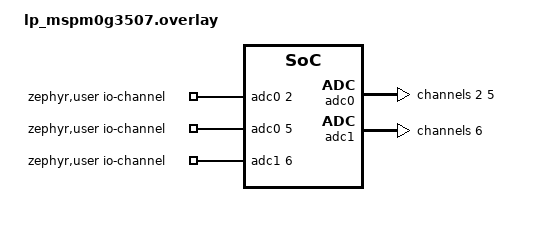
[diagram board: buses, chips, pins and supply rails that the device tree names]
/*
 * SPDX-License-Identifier: Apache-2.0
 */

/ {
	zephyr,user {
		/* adjust channel number according to pinmux in lp_mspm0g3507.dts */
		io-channels = <&adc0 2 &adc0 5 &adc1 6>;	/* I.e. A0.2 = PA25 */
	};
};

&adc0 {
	status = "okay";

	#address-cells = <1>;
	#size-cells = <0>;

	channel@2 {
		reg = <2>;
		zephyr,gain = "ADC_GAIN_1";
		zephyr,reference = "ADC_REF_INTERNAL";
		zephyr,acquisition-time = <ADC_ACQ_TIME(ADC_ACQ_TIME_TICKS, 500)>;
		zephyr,resolution = <12>;
	};

	channel@5 {
		reg = <5>;
		zephyr,gain = "ADC_GAIN_1";
		zephyr,reference = "ADC_REF_INTERNAL";
		zephyr,acquisition-time = <ADC_ACQ_TIME(ADC_ACQ_TIME_TICKS, 200)>;
		zephyr,resolution = <12>;
	};
};

&adc1 {
	status = "okay";

	#address-cells = <1>;
	#size-cells = <0>;

	channel@6 {
		reg = <6>;
		zephyr,gain = "ADC_GAIN_1";
		zephyr,reference = "ADC_REF_VDD_1";
		zephyr,acquisition-time = <ADC_ACQ_TIME(ADC_ACQ_TIME_TICKS, 500)>;
		zephyr,resolution = <12>;
		zephyr,oversampling = <128>;
	};
};
